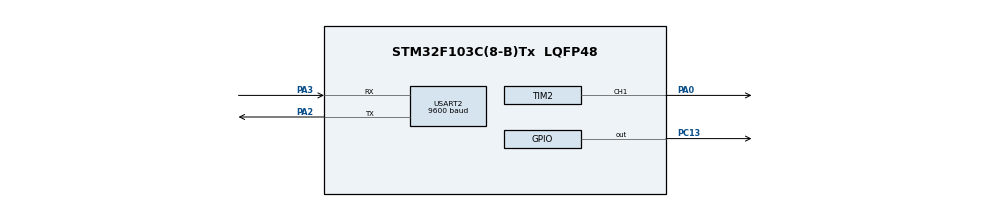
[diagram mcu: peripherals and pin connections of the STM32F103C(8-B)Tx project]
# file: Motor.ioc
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Mcu.Family=STM32F1
Mcu.Name=STM32F103C(8-B)Tx
Mcu.Package=LQFP48
NVIC.PriorityGroup=NVIC_PRIORITYGROUP_4
PA0-WKUP.Signal=S_TIM2_CH1_ETR
PA13.Mode=Serial_Wire
PA13.Signal=SYS_JTMS-SWDIO
PA14.Mode=Serial_Wire
PA14.Signal=SYS_JTCK-SWCLK
PA2.Mode=Asynchronous
PA2.Signal=USART2_TX
PA3.Mode=Asynchronous
PA3.Signal=USART2_RX
PC13-TAMPER-RTC.Signal=GPIO_Output
ProjectManager.HeapSize=0x200
ProjectManager.StackSize=0x400
ProjectManager.TargetToolchain=STM32CubeIDE
RCC.APB1Freq_Value=8000000
RCC.APB2Freq_Value=8000000
SH.S_TIM2_CH1_ETR.0=TIM2_CH1,PWM Generation1 CH1
TIM2.Channel-PWM\ Generation1\ CH1=TIM_CHANNEL_1
TIM2.CounterMode=TIM_COUNTERMODE_UP
TIM2.OC1Preload_PWM=DISABLE
TIM2.OCFastMode_PWM-PWM\ Generation1\ CH1=TIM_OCFAST_DISABLE
TIM2.Period=2019
TIM2.Prescaler=79
TIM2.Pulse-PWM\ Generation1\ CH1=0
USART2.BaudRate=9600
USART2.VirtualMode=VM_ASYNC
VP_RTC_No_RTC_Output.Mode=RTC_OUT_NO
VP_RTC_VS_RTC_Activate.Mode=RTC_Enabled
VP_TIM2_VS_ClockSourceINT.Mode=Internal
board=custom

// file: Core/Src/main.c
/* USER CODE BEGIN Header */
/**
  ******************************************************************************
  * @file           : main.c
  * @brief          : Main program body
  ******************************************************************************
  * @attention
  *
  * <h2><center>&copy; Copyright (c) 2020 STMicroelectronics.
  * All rights reserved.</center></h2>
  *
  * This software component is licensed by ST under BSD 3-Clause license,
  * the "License"; You may not use this file except in compliance with the
  * License. You may obtain a copy of the License at:
  *                        opensource.org/licenses/BSD-3-Clause
  *
  ******************************************************************************
  */
/* USER CODE END Header */

#include "main.h"

/* USER CODE BEGIN Includes */
#include <stm32f1xx.h>
#include "servo.h"
#include <stdio.h>

/* USER CODE END Includes */

/* USER CODE BEGIN PTD */
#ifdef __GNUC__
  /* With GCC, small printf (option LD Linker->Libraries->Small printf
     set to 'Yes') calls __io_putchar() */
  #define PUTCHAR_PROTOTYPE int __io_putchar(int ch)
#else
	#define PUTCHAR_PROTOTYPE int fputc(int ch, FILE *f)
#endif /* __GNUC__ */

/* USER CODE END PTD */

RTC_HandleTypeDef hrtc;

TIM_HandleTypeDef htim2;

UART_HandleTypeDef huart2;

void SystemClock_Config(void);
static void MX_GPIO_Init(void);
static void MX_RTC_Init(void);
static void MX_TIM2_Init(void);
static void MX_USART2_UART_Init(void);

/* USER CODE BEGIN 0 */
/*
int write(int file, char *ptr, int len){
	for(int i = 0; i < len; i++){
		ITM_SendChar(*ptr++);
	}
	return len;
}
*/
/* USER CODE END 0 */

int main(void)
{

  /* MCU Configuration--------------------------------------------------------*/

  /* Reset of all peripherals, Initializes the Flash interface and the Systick. */
  HAL_Init();

  /* Configure the system clock */
  SystemClock_Config();

  /* Initialize all configured peripherals */
  MX_GPIO_Init();
  MX_RTC_Init();
  MX_TIM2_Init();
  MX_USART2_UART_Init();
  /* USER CODE BEGIN 2 */
  HAL_TIM_PWM_Start(&htim2,TIM_CHANNEL_1);

  /* USER CODE END 2 */

  /* Infinite loop */
  /* USER CODE BEGIN WHILE */
  while (1)
  {
	  set_angle(&htim2, 90);

    /* USER CODE END WHILE */

  }
}

void SystemClock_Config(void)
{
  RCC_OscInitTypeDef RCC_OscInitStruct = {0};
  RCC_ClkInitTypeDef RCC_ClkInitStruct = {0};
  RCC_PeriphCLKInitTypeDef PeriphClkInit = {0};

  /** Initializes the CPU, AHB and APB busses clocks
  */
  RCC_OscInitStruct.OscillatorType = RCC_OSCILLATORTYPE_HSI|RCC_OSCILLATORTYPE_LSI;
  RCC_OscInitStruct.HSIState = RCC_HSI_ON;
  RCC_OscInitStruct.HSICalibrationValue = RCC_HSICALIBRATION_DEFAULT;
  RCC_OscInitStruct.LSIState = RCC_LSI_ON;
  RCC_OscInitStruct.PLL.PLLState = RCC_PLL_NONE;
  if (HAL_RCC_OscConfig(&RCC_OscInitStruct) != HAL_OK)
  {
    Error_Handler();
  }
  /** Initializes the CPU, AHB and APB busses clocks
  */
  RCC_ClkInitStruct.ClockType = RCC_CLOCKTYPE_HCLK|RCC_CLOCKTYPE_SYSCLK
                              |RCC_CLOCKTYPE_PCLK1|RCC_CLOCKTYPE_PCLK2;
  RCC_ClkInitStruct.SYSCLKSource = RCC_SYSCLKSOURCE_HSI;
  RCC_ClkInitStruct.AHBCLKDivider = RCC_SYSCLK_DIV1;
  RCC_ClkInitStruct.APB1CLKDivider = RCC_HCLK_DIV1;
  RCC_ClkInitStruct.APB2CLKDivider = RCC_HCLK_DIV1;

  if (HAL_RCC_ClockConfig(&RCC_ClkInitStruct, FLASH_LATENCY_0) != HAL_OK)
  {
    Error_Handler();
  }
  PeriphClkInit.PeriphClockSelection = RCC_PERIPHCLK_RTC;
  PeriphClkInit.RTCClockSelection = RCC_RTCCLKSOURCE_LSI;
  if (HAL_RCCEx_PeriphCLKConfig(&PeriphClkInit) != HAL_OK)
  {
    Error_Handler();
  }
}

static void MX_RTC_Init(void)
{

  RTC_TimeTypeDef sTime = {0};
  RTC_DateTypeDef DateToUpdate = {0};

  /** Initialize RTC Only
  */
  hrtc.Instance = RTC;
  hrtc.Init.AsynchPrediv = RTC_AUTO_1_SECOND;
  hrtc.Init.OutPut = RTC_OUTPUTSOURCE_NONE;
  if (HAL_RTC_Init(&hrtc) != HAL_OK)
  {
    Error_Handler();
  }

  /** Initialize RTC and set the Time and Date
  */
  sTime.Hours = 0x0;
  sTime.Minutes = 0x0;
  sTime.Seconds = 0x0;

  if (HAL_RTC_SetTime(&hrtc, &sTime, RTC_FORMAT_BCD) != HAL_OK)
  {
    Error_Handler();
  }
  DateToUpdate.WeekDay = RTC_WEEKDAY_MONDAY;
  DateToUpdate.Month = RTC_MONTH_JANUARY;
  DateToUpdate.Date = 0x1;
  DateToUpdate.Year = 0x0;

  if (HAL_RTC_SetDate(&hrtc, &DateToUpdate, RTC_FORMAT_BCD) != HAL_OK)
  {
    Error_Handler();
  }

}

static void MX_TIM2_Init(void)
{

  TIM_ClockConfigTypeDef sClockSourceConfig = {0};
  TIM_MasterConfigTypeDef sMasterConfig = {0};
  TIM_OC_InitTypeDef sConfigOC = {0};

  htim2.Instance = TIM2;
  htim2.Init.Prescaler = 79;
  htim2.Init.CounterMode = TIM_COUNTERMODE_UP;
  htim2.Init.Period = 2019;
  htim2.Init.ClockDivision = TIM_CLOCKDIVISION_DIV1;
  htim2.Init.AutoReloadPreload = TIM_AUTORELOAD_PRELOAD_DISABLE;
  if (HAL_TIM_Base_Init(&htim2) != HAL_OK)
  {
    Error_Handler();
  }
  sClockSourceConfig.ClockSource = TIM_CLOCKSOURCE_INTERNAL;
  if (HAL_TIM_ConfigClockSource(&htim2, &sClockSourceConfig) != HAL_OK)
  {
    Error_Handler();
  }
  if (HAL_TIM_PWM_Init(&htim2) != HAL_OK)
  {
    Error_Handler();
  }
  sMasterConfig.MasterOutputTrigger = TIM_TRGO_RESET;
  sMasterConfig.MasterSlaveMode = TIM_MASTERSLAVEMODE_DISABLE;
  if (HAL_TIMEx_MasterConfigSynchronization(&htim2, &sMasterConfig) != HAL_OK)
  {
    Error_Handler();
  }
  sConfigOC.OCMode = TIM_OCMODE_PWM1;
  sConfigOC.Pulse = 0;
  sConfigOC.OCPolarity = TIM_OCPOLARITY_HIGH;
  sConfigOC.OCFastMode = TIM_OCFAST_DISABLE;
  if (HAL_TIM_PWM_ConfigChannel(&htim2, &sConfigOC, TIM_CHANNEL_1) != HAL_OK)
  {
    Error_Handler();
  }
  __HAL_TIM_DISABLE_OCxPRELOAD(&htim2, TIM_CHANNEL_1);
  HAL_TIM_MspPostInit(&htim2);

}

static void MX_USART2_UART_Init(void)
{

  huart2.Instance = USART2;
  huart2.Init.BaudRate = 9600;
  huart2.Init.WordLength = UART_WORDLENGTH_8B;
  huart2.Init.StopBits = UART_STOPBITS_1;
  huart2.Init.Parity = UART_PARITY_NONE;
  huart2.Init.Mode = UART_MODE_TX_RX;
  huart2.Init.HwFlowCtl = UART_HWCONTROL_NONE;
  huart2.Init.OverSampling = UART_OVERSAMPLING_16;
  if (HAL_UART_Init(&huart2) != HAL_OK)
  {
    Error_Handler();
  }

}

static void MX_GPIO_Init(void)
{
  GPIO_InitTypeDef GPIO_InitStruct = {0};

  /* GPIO Ports Clock Enable */
  __HAL_RCC_GPIOC_CLK_ENABLE();
  __HAL_RCC_GPIOA_CLK_ENABLE();

  /*Configure GPIO pin Output Level */
  HAL_GPIO_WritePin(GPIOC, GPIO_PIN_13, GPIO_PIN_RESET);

  /*Configure GPIO pin : PC13 */
  GPIO_InitStruct.Pin = GPIO_PIN_13;
  GPIO_InitStruct.Mode = GPIO_MODE_OUTPUT_PP;
  GPIO_InitStruct.Pull = GPIO_NOPULL;
  GPIO_InitStruct.Speed = GPIO_SPEED_FREQ_LOW;
  HAL_GPIO_Init(GPIOC, &GPIO_InitStruct);

}

/* USER CODE BEGIN 4 */
PUTCHAR_PROTOTYPE
{
  /* Place your implementation of fputc here */
  /* e.g. write a character to the EVAL_COM1 and Loop until the end of transmission */
  HAL_UART_Transmit(&huart2, (uint8_t *)&ch, 1, 0xFFFF);

  return ch;
}

/* USER CODE END 4 */

void Error_Handler(void)
{
}

/************************ (C) COPYRIGHT STMicroelectronics *****END OF FILE****/
